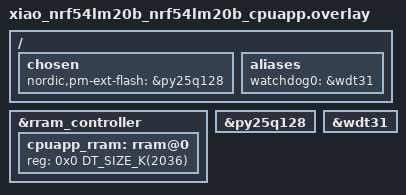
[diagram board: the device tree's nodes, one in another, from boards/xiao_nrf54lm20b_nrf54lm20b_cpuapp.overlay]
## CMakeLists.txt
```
#
# Copyright (c) 2021 Nordic Semiconductor ASA
#
# SPDX-License-Identifier: LicenseRef-Nordic-5-Clause
#

cmake_minimum_required(VERSION 3.20.0)

find_package(Zephyr HINTS $ENV{ZEPHYR_BASE})

project(template)

# Enable GNU STD support.
include(${ZEPHYR_CONNECTEDHOMEIP_MODULE_DIR}/config/nrfconnect/app/enable-gnu-std.cmake)

# NORDIC SDK APP START

# Include all source files that are located in the Matter common directory.
include(${ZEPHYR_NRF_MODULE_DIR}/samples/matter/common/cmake/source_common.cmake)

# Include Data Model utils
include(${ZEPHYR_NRF_MODULE_DIR}/samples/matter/common/cmake/data_model.cmake)

include(${ZEPHYR_NRF_MODULE_DIR}/samples/matter/common/cmake/zap_helpers.cmake)
ncs_get_zap_parent_dir(ZAP_PARENT_DIR)

target_include_directories(app PRIVATE
  src
  ${ZAP_PARENT_DIR}
)

target_sources(app PRIVATE
  src/app_task.cpp
  src/main.cpp
)

ncs_configure_data_model()
# NORDIC SDK APP END
```

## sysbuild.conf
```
#
# Copyright (c) 2024 Nordic Semiconductor
#
# SPDX-License-Identifier: LicenseRef-Nordic-5-Clause
#

SB_CONFIG_MATTER=y

# Use the shipped USB firmware loader's slot-0 layout (starts at 0x6000).
SB_CONFIG_PARTITION_MANAGER=y
SB_CONFIG_MCUBOOT_MODE_OVERWRITE_ONLY=y

# The Matter sysbuild generator is controlled by this sysbuild option; the
# legacy CONFIG_CHIP_FACTORY_DATA_BUILD setting does not disable it in NCS 3.3.
SB_CONFIG_MATTER_FACTORY_DATA_GENERATE=n
```

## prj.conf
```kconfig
#
# Copyright (c) 2021 Nordic Semiconductor ASA
#
# SPDX-License-Identifier: LicenseRef-Nordic-5-Clause
#

# This sample uses Kconfig.defaults to set options common for all
# samples. This file should contain only options specific for this sample
# or overrides of default values.

# Enable CHIP
CONFIG_CHIP=y
CONFIG_CHIP_PROJECT_CONFIG="src/chip_project_config.h"
CONFIG_CHIP_DEVICE_PRODUCT_NAME="Matter Template"

# Configure ZAP file name
CONFIG_NCS_SAMPLE_MATTER_ZAP_FILE_PATH="${APPLICATION_CONFIG_DIR}/src/default_zap/template.zap"

# 32768 == 0x8000 (example Product ID added temporaly,
# but it must be changed with proper PID from the list:
# https://github.com/project-chip/connectedhomeip/blob/482e6fd03196a6de45465a90003947ef4b86e0b1/docs/examples/discussion/PID_allocation_for_example_apps.md)
CONFIG_CHIP_DEVICE_PRODUCT_ID=32768
CONFIG_STD_CPP17=y

# Enable Matter pairing automatically on application start.
CONFIG_CHIP_ENABLE_PAIRING_AUTOSTART=y

# Enable Matter extended announcement and increase duration to 1 hour.
CONFIG_CHIP_BLE_EXT_ADVERTISING=y
CONFIG_CHIP_BLE_ADVERTISING_DURATION=60

# Add support for LEDs and buttons on Nordic development kits
CONFIG_DK_LIBRARY=y

# Bluetooth Low Energy configuration
CONFIG_BT_DEVICE_NAME="MatterTemplate"

# Other settings
CONFIG_THREAD_NAME=y
CONFIG_MPU_STACK_GUARD=y
CONFIG_RESET_ON_FATAL_ERROR=n
CONFIG_CHIP_LIB_SHELL=y
CONFIG_NCS_SAMPLE_MATTER_TEST_SHELL=y

# Disable NFC onboarding
CONFIG_CHIP_NFC_ONBOARDING_PAYLOAD=n

# Reduce application size
CONFIG_USE_SEGGER_RTT=n

# Enable Factory Data feature
# Temporarily disabled (NONE backend) to test crash cause under factory firmware loader.
# The default NRFCONNECT_BACKEND `select CHIP_FACTORY_DATA`, overriding =n; NONE avoids that.
CONFIG_CHIP_FACTORY_DATA_NONE=y
CONFIG_CHIP_FACTORY_DATA_BUILD=n
CONFIG_BOOTLOADER_MCUBOOT=y
```

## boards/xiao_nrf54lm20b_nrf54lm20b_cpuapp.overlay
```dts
/*
 * XIAO nRF54LM20B Matter configuration with the external PY25Q128HA.
 */

/ {
	chosen {
		nordic,pm-ext-flash = &py25q128;
	};

	aliases {
		watchdog0 = &wdt31;
	};
};

&rram_controller {
	cpuapp_rram: rram@0 {
		reg = <0x0 DT_SIZE_K(2036)>;
		ranges = <0x0 0x0 DT_SIZE_K(2036)>;
	};
};

&py25q128 {
	status = "okay";
};

&wdt31 {
	status = "okay";
};
```

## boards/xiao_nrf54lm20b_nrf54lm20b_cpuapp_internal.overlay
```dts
/*
 * XIAO nRF54LM20B Matter configuration with both MCUboot slots in RRAM.
 */

/ {
	aliases {
		watchdog0 = &wdt31;
	};
};

&rram_controller {
	cpuapp_rram: rram@0 {
		reg = <0x0 DT_SIZE_K(2036)>;
		ranges = <0x0 0x0 DT_SIZE_K(2036)>;
	};
};

&py25q128 {
	status = "disabled";
};

&wdt31 {
	status = "okay";
};
```

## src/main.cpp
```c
/*
 * Copyright (c) 2021 Nordic Semiconductor ASA
 *
 * SPDX-License-Identifier: LicenseRef-Nordic-5-Clause
 */

#include "app_task.h"

#include <zephyr/logging/log.h>
#include <zephyr/kernel.h>

LOG_MODULE_REGISTER(app, CONFIG_CHIP_APP_LOG_LEVEL);

int main()
{
	LOG_INF("Matter application starting");

	CHIP_ERROR err = AppTask::Instance().StartApp();

	LOG_ERR("Matter startup failed with code %" CHIP_ERROR_FORMAT, err.Format());

	/* When the LED is available, blink it rapidly to signal the error (the loop's k_sleep yields the CPU,
	 * so USB CDC / shell remain diagnosable); if the LED was never initialized (failure before Board::Init),
	 * this returns immediately and we fall through to the sleep loop below.
	 */
	AppTask::Instance().IndicateFatalError();

	/* Keep USB CDC and the shell alive when Matter startup fails so the board
	 * remains diagnosable over its serial console instead of halting here.
	 */
	while (true) {
		k_sleep(K_SECONDS(1));
	}
}
```

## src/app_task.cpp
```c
/*
 * Copyright (c) 2021 Nordic Semiconductor ASA
 *
 * SPDX-License-Identifier: LicenseRef-Nordic-5-Clause
 */

#include "app_task.h"

#include "app/matter_init.h"
#include "app/task_executor.h"
#include "board/board.h"
#include "lib/core/CHIPError.h"
#include "lib/support/CodeUtils.h"

#include <setup_payload/OnboardingCodesUtil.h>

#include <zephyr/kernel.h>
#include <zephyr/logging/log.h>

LOG_MODULE_DECLARE(app, CONFIG_CHIP_APP_LOG_LEVEL);

using namespace ::chip;
using namespace ::chip::app;
using namespace ::chip::DeviceLayer;

namespace {
/* Single-flash timing: on 120ms, in-group gap 120ms, between-group pause 450ms for easy counting. */
constexpr uint32_t kFlashOnMs  = 120;
constexpr uint32_t kFlashOffMs = 120;
constexpr uint32_t kFlashGapMs = 450;
/* Fast-flash timing used to signal a failure. */
constexpr uint32_t kFatalOnMs  = 80;
constexpr uint32_t kFatalOffMs = 80;

/* Only set to true after Board::Init() succeeds, ensuring the failure path never touches an uninitialized LED. */
bool sLedReady = false;

/* Synchronously blink count times as a stage-progress indicator. Only called after Board::Init().
 * Uses Set() + k_sleep instead of Blink() so the count is deterministic and unaffected by async timers,
 * and Set() also stops the status-indication timer started during Board init to avoid conflicts.
 */
void FlashLedTimes(uint8_t count)
{
	if (!sLedReady) {
		return;
	}
	Nrf::LEDWidget &led = Nrf::GetBoard().GetLED(Nrf::DeviceLeds::LED1);
	for (uint8_t i = 0; i < count; i++) {
		led.Set(true);
		k_sleep(K_MSEC(kFlashOnMs));
		led.Set(false);
		k_sleep(K_MSEC((i + 1 < count) ? kFlashOffMs : kFlashGapMs));
	}
}
} /* namespace */

CHIP_ERROR AppTask::Init()
{
	/* Initialize Matter stack */
	ReturnErrorOnFailure(Nrf::Matter::PrepareServer());

	if (!Nrf::GetBoard().Init()) {
		LOG_ERR("User interface initialization failed.");
		return CHIP_ERROR_INCORRECT_STATE;
	}
	sLedReady = true;
	LOG_INF("stage 1/3: board UI ready");
	FlashLedTimes(1); /* stage 1: on-board peripherals (LED/button) ready */

	/* Register Matter event handler that controls the connectivity status LED based on the captured Matter network
	 * state. */
	ReturnErrorOnFailure(Nrf::Matter::RegisterEventHandler(Nrf::Board::DefaultMatterEventHandler, 0));
	LOG_INF("stage 2/3: matter event handler registered");
	FlashLedTimes(2); /* stage 2: Matter event handler registered */

	ReturnErrorOnFailure(Nrf::Matter::StartServer());
	LOG_INF("stage 3/3: matter server started, entering main loop");
	FlashLedTimes(3); /* stage 3: server started, about to enter advertising/main loop; LED then handed to the connectivity-status indicator */

	return CHIP_NO_ERROR;
}

CHIP_ERROR AppTask::StartApp()
{
	ReturnErrorOnFailure(Init());

	while (true) {
		Nrf::DispatchNextTask();
	}

	return CHIP_NO_ERROR;
}

void AppTask::IndicateFatalError()
{
	if (!sLedReady) {
		return;
	}
	Nrf::LEDWidget &led = Nrf::GetBoard().GetLED(Nrf::DeviceLeds::LED1);
	while (true) {
		led.Set(true);
		k_sleep(K_MSEC(kFatalOnMs));
		led.Set(false);
		k_sleep(K_MSEC(kFatalOffMs));
	}
}
```

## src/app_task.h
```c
/*
 * Copyright (c) 2021 Nordic Semiconductor ASA
 *
 * SPDX-License-Identifier: LicenseRef-Nordic-5-Clause
 */

#pragma once

#include <platform/CHIPDeviceLayer.h>

struct k_timer;

class AppTask {
public:
	static AppTask &Instance()
	{
		static AppTask sAppTask;
		return sAppTask;
	};

	CHIP_ERROR StartApp();

	/* On startup failure, blink the on-board LED rapidly to signal the error;
	 * if the LED is not initialized yet (failure before Board::Init), just
	 * return and leave the serial console diagnosable for the caller.
	 */
	void IndicateFatalError();

private:
	CHIP_ERROR Init();
};
```
